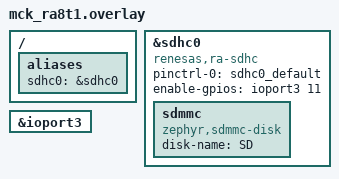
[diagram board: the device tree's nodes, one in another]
/*
 * Copyright (c) 2024 Renesas Electronics Corporation
 * SPDX-License-Identifier: Apache-2.0
 */

/ {
	aliases {
		sdhc0 = &sdhc0;
	};
};

&sdhc0 {
	compatible = "renesas,ra-sdhc";
	pinctrl-0 = <&sdhc0_default>;
	enable-gpios = <&ioport3 11 GPIO_ACTIVE_HIGH>;
	pinctrl-names = "default";
	status = "okay";
	sdmmc {
		compatible = "zephyr,sdmmc-disk";
		disk-name = "SD";
		status = "okay";
	};
};

&ioport3 {
	status = "okay";
};
